VERSION ""

NS_ :

BS_:

BU_:

BO_ 1312 GWAY1: 8 Vector__XXX
 SG_ Gway_Cluster_Odometer : 0|24@1+ (0.1,0) [0|0] "km" Vector__XXX

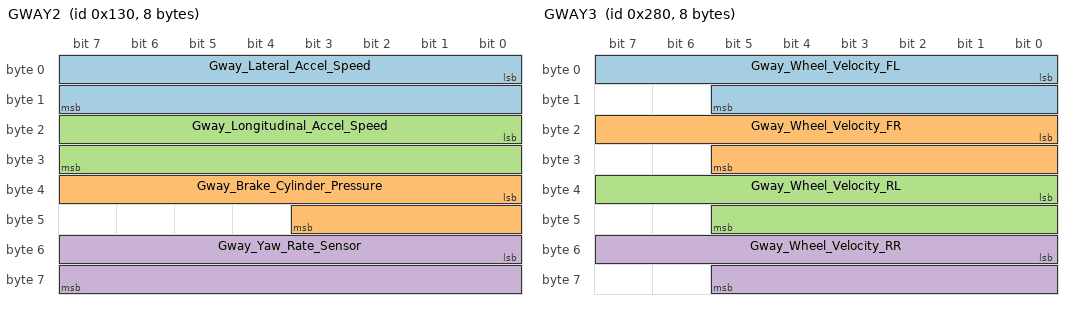
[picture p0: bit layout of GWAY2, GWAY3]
BO_ 304 GWAY2: 8 Vector__XXX
 SG_ Gway_Lateral_Accel_Speed : 0|16@1+ (0.000127465,-4.17677) [0|0] "g" Vector__XXX
 SG_ Gway_Brake_Cylinder_Pressure : 32|12@1+ (0.1,0) [0|0] "Bar" Vector__XXX
 SG_ Gway_Longitudinal_Accel_Speed : 16|16@1+ (0.000127465,-4.17677) [0|0] "g" Vector__XXX
 SG_ Gway_Yaw_Rate_Sensor : 48|16@1+ (0.005,-163.84) [0|0] "��/s" Vector__XXX

BO_ 640 GWAY3: 8 Vector__XXX
 SG_ Gway_Wheel_Velocity_FL : 0|14@1+ (0.03125,0) [0|0] "km/h" Vector__XXX
 SG_ Gway_Wheel_Velocity_FR : 16|14@1+ (0.03125,0) [0|0] "km/h" Vector__XXX
 SG_ Gway_Wheel_Velocity_RL : 32|14@1+ (0.03125,0) [0|0] "km/h" Vector__XXX
 SG_ Gway_Wheel_Velocity_RR : 48|14@1+ (0.03125,0) [0|0] "km/h" Vector__XXX

BO_ 656 GWAY4: 8 Vector__XXX
 SG_ Gway_Steering_Angle : 24|16@1- (0.1,0) [0|0] "Deg" Vector__XXX

BO_ 608 GWAY5: 8 Vector__XXX
 SG_ Gway_Brake_Active : 0|8@1+ (1,0) [0|0] "" Vector__XXX

BO_ 368 GWAY6: 8 Vector__XXX
 SG_ Gway_Accel_Pedal_Position : 32|8@1+ (0.392157,0) [0|100] "%" Vector__XXX
 SG_ Gway_GearSelDisp : 11|4@1+ (1,0) [0|0] "" Vector__XXX

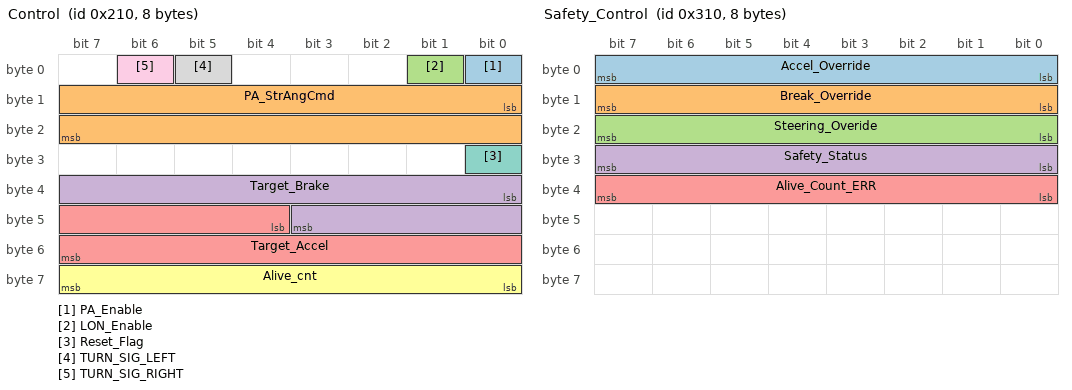
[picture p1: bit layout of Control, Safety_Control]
BO_ 528 Control: 8 Vector__XXX
 SG_ PA_Enable : 0|1@1+ (1,0) [0|0] "" Vector__XXX
 SG_ PA_StrAngCmd : 8|16@1- (0.1,0) [0|0] "Deg" Vector__XXX
 SG_ LON_Enable : 1|1@1+ (1,0) [0|0] "" Vector__XXX
 SG_ Target_Brake : 32|12@1+ (0.1,0) [0|100] "" Vector__XXX
 SG_ Target_Accel : 44|12@1+ (0.1,0) [0|100] "%" Vector__XXX
 SG_ Alive_cnt : 56|8@1+ (1,0) [0|255] "" Vector__XXX
 SG_ Reset_Flag : 24|1@1+ (1,0) [0|0] "" Vector__XXX
 SG_ TURN_SIG_LEFT : 5|1@1+ (1,0) [0|1] "" Vector__XXX
 SG_ TURN_SIG_RIGHT : 6|1@1+ (1,0) [0|1] "" Vector__XXX

BO_ 784 Safety_Control: 8 Vector__XXX
 SG_ Accel_Override : 0|8@1+ (1,0) [0|0] "" Vector__XXX
 SG_ Break_Override : 8|8@1+ (1,0) [0|0] "" Vector__XXX
 SG_ Steering_Overide : 16|8@1+ (1,0) [0|0] "" Vector__XXX
 SG_ Safety_Status : 24|8@1+ (1,0) [0|0] "" Vector__XXX
 SG_ Alive_Count_ERR : 32|8@1+ (1,0) [0|1] "" Vector__XXX

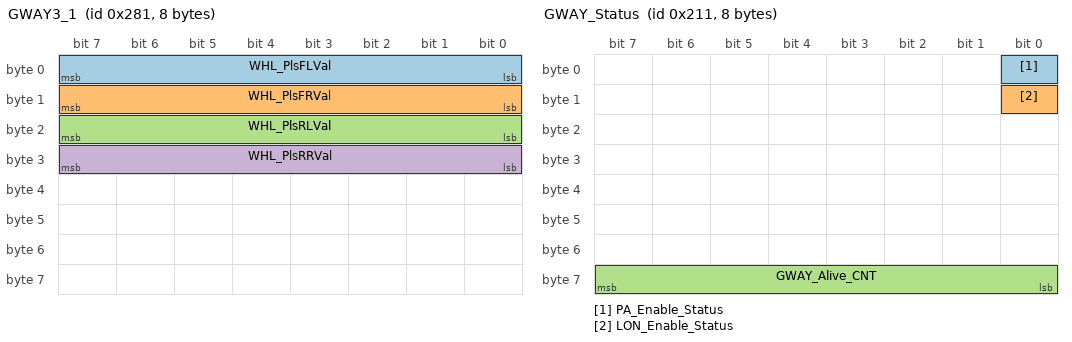
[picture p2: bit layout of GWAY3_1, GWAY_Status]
BO_ 641 GWAY3_1: 8 Vector__XXX
 SG_ WHL_PlsFLVal : 0|8@1+ (0.5,0) [0|0] "pulse count" Vector__XXX
 SG_ WHL_PlsFRVal : 8|8@1+ (0.5,0) [0|0] "pulse count" Vector__XXX
 SG_ WHL_PlsRLVal : 16|8@1+ (0.5,0) [0|0] "pulse count" Vector__XXX
 SG_ WHL_PlsRRVal : 24|8@1+ (0.5,0) [0|0] "pulse count" Vector__XXX

BO_ 529 GWAY_Status: 8 Vector__XXX
 SG_ PA_Enable_Status : 0|1@1+ (1,0) [0|0] "" Vector__XXX
 SG_ LON_Enable_Status : 8|1@1+ (1,0) [0|0] "" Vector__XXX
 SG_ GWAY_Alive_CNT : 56|8@1+ (1,0) [0|0] "" Vector__XXX

CM_ SG_ 528 PA_Enable "Lateral Controller Enable";
CM_ SG_ 528 PA_StrAngCmd "Target Steering Angle";
CM_ SG_ 528 LON_Enable "Longitudinal Controller Enable";
CM_ SG_ 528 Alive_cnt "AliveCnt step size = 1";
VAL_ 368 Gway_GearSelDisp 0 "P" 5 "D" 6 "N" 7 "R" ;
VAL_ 528 PA_Enable 0 "Disable" 1 "Enable" ;
VAL_ 528 LON_Enable 0 "Disable" 1 "Enable" ;
